# PIC32MM0256GPM048 register map
Vendor: Microchip
Registers are 32-bit, read-write, reset 0x0 unless marked. A register's access mark holds for its fields unless they carry their own. Addresses are absolute, and some are shared; only a register's first bit layout is shown; [hi:lo] are bit positions; {n}, {i} and the like mark numbered series.

## HLVD
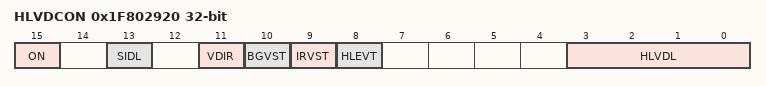
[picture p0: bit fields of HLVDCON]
0x1F802920 HLVDCON
  [15] ON, [13] SIDL, [11] VDIR, [10] BGVST, [9] IRVST, [8] HLEVT, [3:0] HLVDL

## NVM
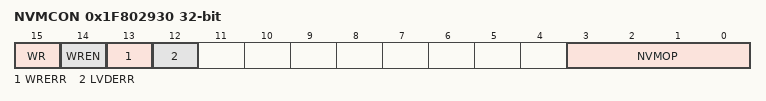
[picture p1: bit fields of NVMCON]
0x1F802930 NVMCON
  [15] WR, [14] WREN, [13] WRERR ro, [12] LVDERR, [3:0] NVMOP

## pfm_ctrl
0x1F802940 NVMKEY wo
0x1F802950 NVMADDR
0x1F802960 NVMDATA0
0x1F802970 NVMDATA1
0x1F802980 NVMSRCADDR
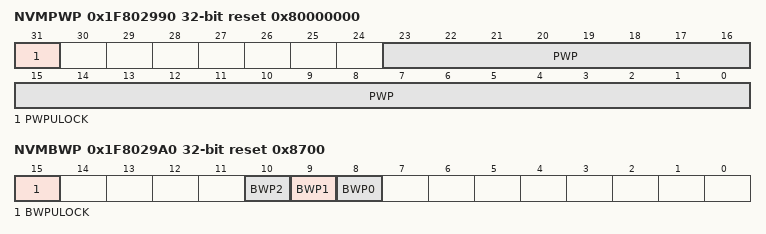
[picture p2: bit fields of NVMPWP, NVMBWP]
0x1F802990 NVMPWP reset 0x80000000
  [31] PWPULOCK — (can only be cleared)
  [23:0] PWP
0x1F8029A0 NVMBWP reset 0x8700
  [15] BWPULOCK — (can only be cleared)
  [10] BWP2
  [9] BWP1
  [8] BWP0

## PORTA
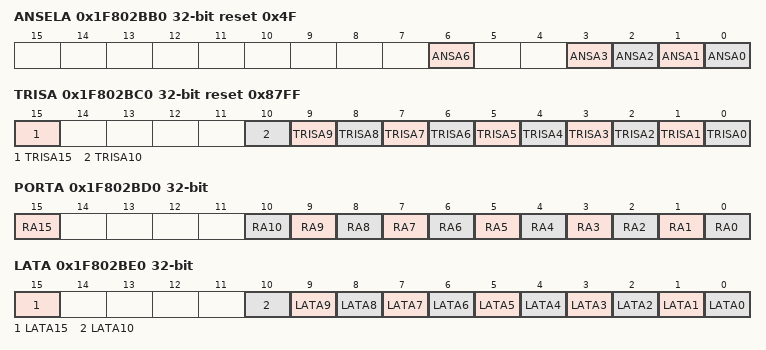
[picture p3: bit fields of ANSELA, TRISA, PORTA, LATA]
0x1F802BB0 ANSELA reset 0x4F
  [6] ANSA6, [n] ANSA{n} (n=0..3)
0x1F802BC0 TRISA reset 0x87FF
  [15] TRISA15, [n] TRISA{n} (n=0..10)
0x1F802BD0 PORTA reset not defined — (power-on value ----------------x----xxxxxxxxxxx)
  [15] RA15, [n] RA{n} (n=0..10)
0x1F802BE0 LATA
  [15] LATA15, [n] LATA{n} (n=0..10)
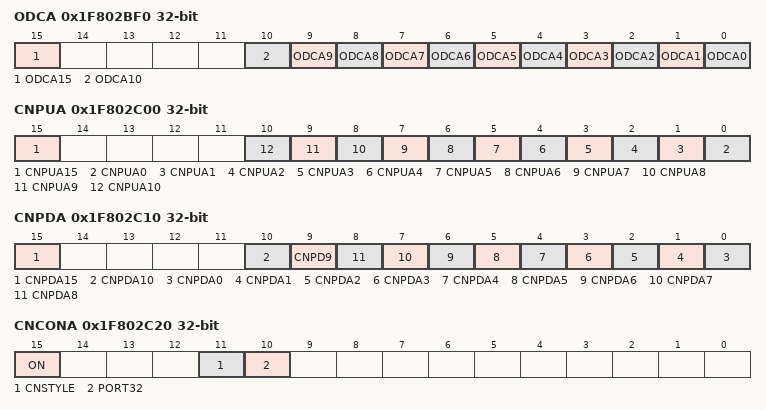
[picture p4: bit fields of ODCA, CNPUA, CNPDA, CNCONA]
0x1F802BF0 ODCA
  [15] ODCA15, [n] ODCA{n} (n=0..10)
0x1F802C00 CNPUA
  [15] CNPUA15, [n] CNPUA{n} (n=0..10)
0x1F802C10 CNPDA
  [15] CNPDA15, [10] CNPDA10, [9] CNPD9, [n] CNPDA{n} (n=0..8)
0x1F802C20 CNCONA
  [15] ON, [11] CNSTYLE, [10] PORT32
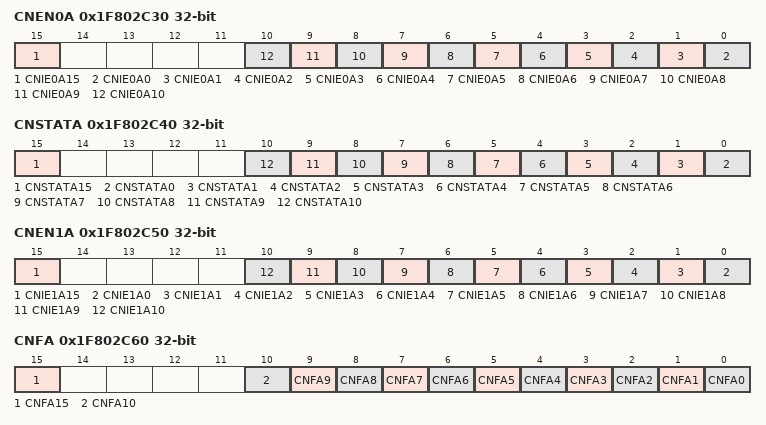
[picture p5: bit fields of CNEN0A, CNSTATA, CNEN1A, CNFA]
0x1F802C30 CNEN0A
  [15] CNIE0A15, [n] CNIE0A{n} (n=0..10)
0x1F802C40 CNSTATA reset not defined — (power-on value ----------------x----xxxxxxxxxxx)
  [15] CNSTATA15, [n] CNSTATA{n} (n=0..10)
0x1F802C50 CNEN1A
  [15] CNIE1A15, [n] CNIE1A{n} (n=0..10)
0x1F802C60 CNFA
  [15] CNFA15, [n] CNFA{n} (n=0..10)
0x1F802C70 SR0A access not given reset not defined
0x1F802C80 SR1A access not given reset not defined

## PORTB
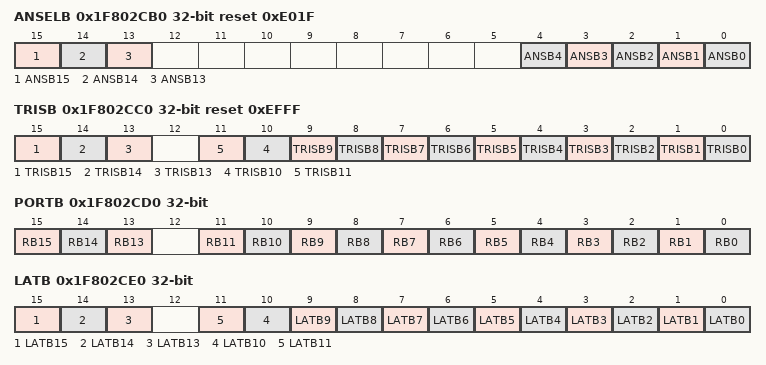
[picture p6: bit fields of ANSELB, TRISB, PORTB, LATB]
0x1F802CB0 ANSELB reset 0xE01F
  [15] ANSB15, [14] ANSB14, [13] ANSB13, [n] ANSB{n} (n=0..4)
0x1F802CC0 TRISB reset 0xEFFF
  [15] TRISB15, [14] TRISB14, [13] TRISB13, [n] TRISB{n} (n=0..11)
0x1F802CD0 PORTB reset not defined — (power-on value ----------------xxx-xxxxxxxxxxxx)
  [15] RB15, [14] RB14, [13] RB13, [n] RB{n} (n=0..11)
0x1F802CE0 LATB
  [15] LATB15, [14] LATB14, [13] LATB13, [n] LATB{n} (n=0..11)
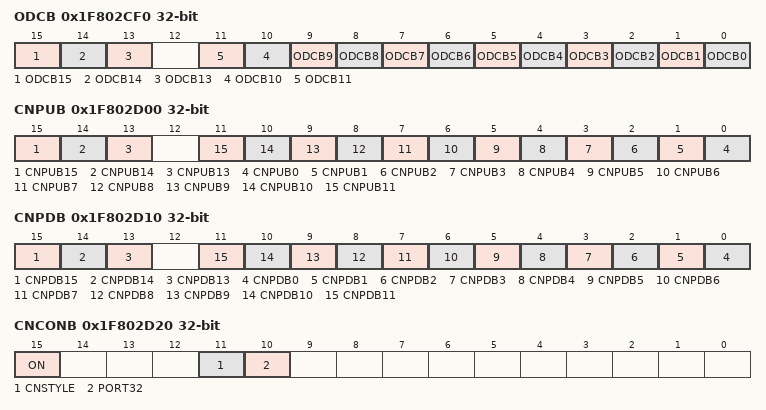
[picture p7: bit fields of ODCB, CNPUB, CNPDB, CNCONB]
0x1F802CF0 ODCB
  [15] ODCB15, [14] ODCB14, [13] ODCB13, [n] ODCB{n} (n=0..11)
0x1F802D00 CNPUB
  [15] CNPUB15, [14] CNPUB14, [13] CNPUB13, [n] CNPUB{n} (n=0..11)
0x1F802D10 CNPDB
  [15] CNPDB15, [14] CNPDB14, [13] CNPDB13, [n] CNPDB{n} (n=0..11)
0x1F802D20 CNCONB
  [15] ON, [11] CNSTYLE, [10] PORT32
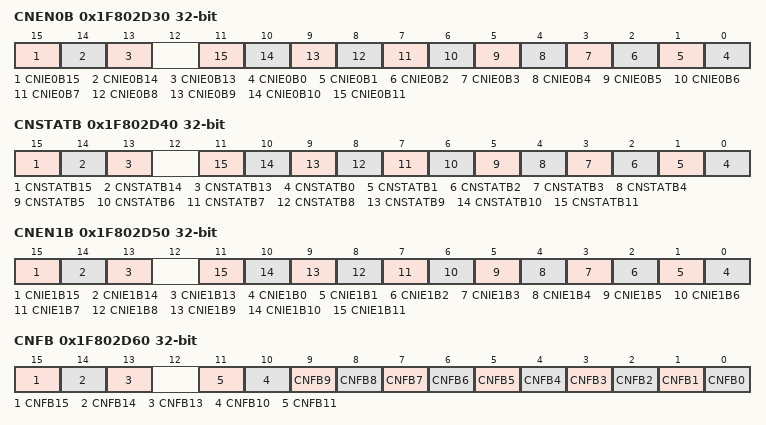
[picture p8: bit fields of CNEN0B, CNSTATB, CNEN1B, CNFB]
0x1F802D30 CNEN0B
  [15] CNIE0B15, [14] CNIE0B14, [13] CNIE0B13, [n] CNIE0B{n} (n=0..11)
0x1F802D40 CNSTATB reset not defined — (power-on value ----------------xxx-xxxxxxxxxxxx)
  [15] CNSTATB15, [14] CNSTATB14, [13] CNSTATB13, [n] CNSTATB{n} (n=0..11)
0x1F802D50 CNEN1B
  [15] CNIE1B15, [14] CNIE1B14, [13] CNIE1B13, [n] CNIE1B{n} (n=0..11)
0x1F802D60 CNFB
  [15] CNFB15, [14] CNFB14, [13] CNFB13, [n] CNFB{n} (n=0..11)
0x1F802D70 SR0B access not given reset not defined
0x1F802D80 SR1B access not given reset not defined

## WDT
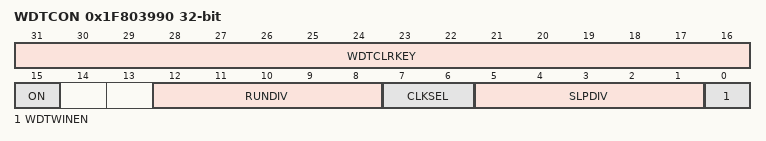
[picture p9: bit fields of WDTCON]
0x1F803990 WDTCON reset not defined — (power-on value 0000000000000000x--xxxxxxxxxxxx0)
  [31:16] WDTCLRKEY wo, [15] ON, [12:8] RUNDIV ro, [7:6] CLKSEL ro, [5:1] SLPDIV ro, [0] WDTWINEN

## TMR1
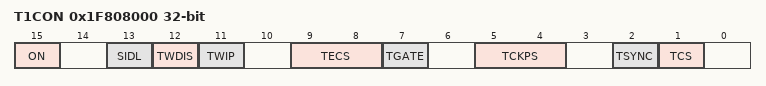
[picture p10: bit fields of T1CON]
0x1F808000 T1CON
  [15] ON, [13] SIDL, [12] TWDIS, [11] TWIP, [9:8] TECS, [7] TGATE, [5:4] TCKPS, [2] TSYNC, [1] TCS
0x1F808010 TMR1
0x1F808020 PR1 reset 0xFFFF

## TMR2
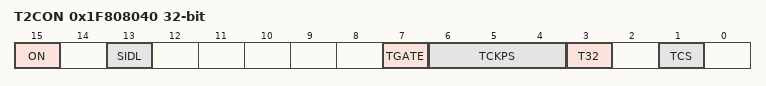
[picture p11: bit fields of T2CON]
0x1F808040 T2CON
  [15] ON, [13] SIDL, [7] TGATE, [6:4] TCKPS, [3] T32, [1] TCS
0x1F808050 TMR2
0x1F808060 PR2 reset 0xFFFF

## TMR3
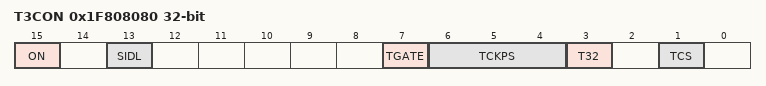
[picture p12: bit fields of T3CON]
0x1F808080 T3CON
  [15] ON, [13] SIDL, [7] TGATE, [6:4] TCKPS, [3] T32, [1] TCS
0x1F808090 TMR3
0x1F8080A0 PR3 reset 0xFFFF

## SPI1
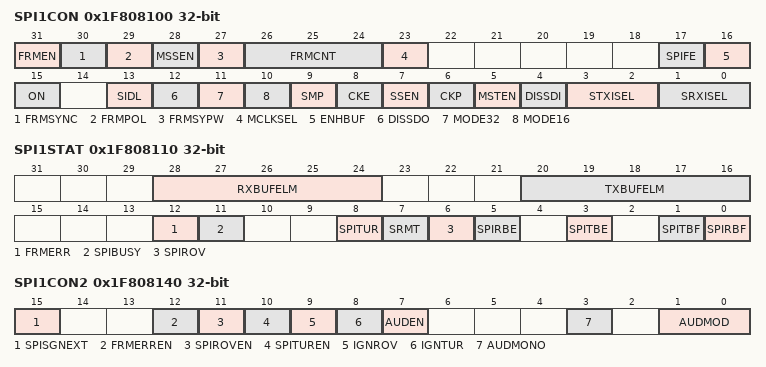
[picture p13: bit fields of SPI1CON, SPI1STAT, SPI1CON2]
0x1F808100 SPI1CON reset not defined — (power-on value 00000000x-----0000000000000x0000)
  [31] FRMEN, [30] FRMSYNC, [29] FRMPOL, [28] MSSEN, [27] FRMSYPW, [26:24] FRMCNT, [23] MCLKSEL, [17] SPIFE, [16] ENHBUF, [15] ON, [13] SIDL, [12] DISSDO, [11] MODE32, [10] MODE16, [9] SMP, [8] CKE, [7] SSEN, [6] CKP, [5] MSTEN, [4] DISSDI, [3:2] STXISEL, [1:0] SRXISEL
0x1F808110 SPI1STAT reset not defined — (power-on value ---00000---00000---x0--0000-0-00)
  [28:24] RXBUFELM ro, [20:16] TXBUFELM ro, [12] FRMERR, [11] SPIBUSY ro, [8] SPITUR ro, [7] SRMT ro, [6] SPIROV ro, [5] SPIRBE ro, [3] SPITBE ro, [1] SPITBF ro, [0] SPIRBF ro
0x1F808120 SPI1BUF reset not defined — (power-on value xxxxxxxxxxxxxxxxxxxxxxxxxxxxxxxx)
0x1F808130 SPI1BRG reset not defined — (power-on value -------------------xxxxxxxxxxxxx)
  [12:0] SPI1BRG
0x1F808140 SPI1CON2 reset not defined — (power-on value ----------------x--xxxxxx---x-xx)
  [15] SPISGNEXT, [12] FRMERREN, [11] SPIROVEN, [10] SPITUREN, [9] IGNROV, [8] IGNTUR, [7] AUDEN, [3] AUDMONO, [1:0] AUDMOD
